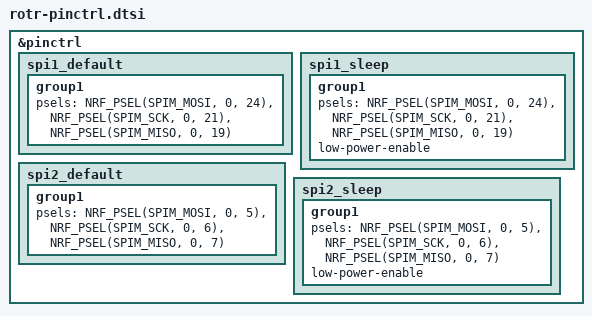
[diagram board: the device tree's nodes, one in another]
/*
 * Copyright (c) 2026 Carl Henriksson
 * SPDX-License-Identifier: MIT
 */

&pinctrl {
	spi1_default: spi1_default {
		group1 {
			psels = <NRF_PSEL(SPIM_MOSI, 0, 24)>,
			        <NRF_PSEL(SPIM_SCK,  0, 21)>,
			        <NRF_PSEL(SPIM_MISO, 0, 19)>;
		};
	};

	spi1_sleep: spi1_sleep {
		group1 {
			psels = <NRF_PSEL(SPIM_MOSI, 0, 24)>,
			        <NRF_PSEL(SPIM_SCK,  0, 21)>,
			        <NRF_PSEL(SPIM_MISO, 0, 19)>;
			low-power-enable;
		};
	};

	/*
	 * WS2812 is write-only; MISO is unused. The Nordic SPIM driver
	 * requires all three pins to be defined regardless.
	 */
	spi2_default: spi2_default {
		group1 {
			psels = <NRF_PSEL(SPIM_MOSI, 0, 5)>,
			        <NRF_PSEL(SPIM_SCK,  0, 6)>,
			        <NRF_PSEL(SPIM_MISO, 0, 7)>;
		};
	};

	spi2_sleep: spi2_sleep {
		group1 {
			psels = <NRF_PSEL(SPIM_MOSI, 0, 5)>,
			        <NRF_PSEL(SPIM_SCK,  0, 6)>,
			        <NRF_PSEL(SPIM_MISO, 0, 7)>;
			low-power-enable;
		};
	};
};
